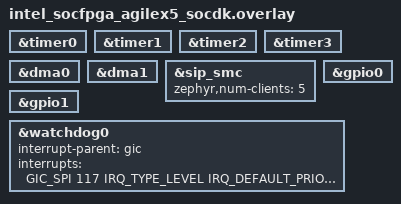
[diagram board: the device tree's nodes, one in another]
/*
 * Copyright (C) 2023 Intel Corporation
 * SPDX-License-Identifier: Apache-2.0
 */

/* The overlay file should be used to enable any
 * dts nodes required by this application for this
 * board.
 */

&timer0 {
	status = "okay";
};

&timer1 {
	status = "okay";
};

&timer2 {
	status = "okay";
};

&timer3 {
	status = "okay";
};

&dma0 {
	status = "okay";
};

&dma1 {
	status = "okay";
};

&sip_smc {
	status = "okay";
	zephyr,num-clients = <5>;
};

&gpio0 {
	status = "okay";
};

&gpio1 {
	status = "okay";
};

&watchdog0 {
	interrupt-parent = <&gic>;
	interrupts = <GIC_SPI 117 IRQ_TYPE_LEVEL
		      IRQ_DEFAULT_PRIORITY>;
	status = "okay";
};
